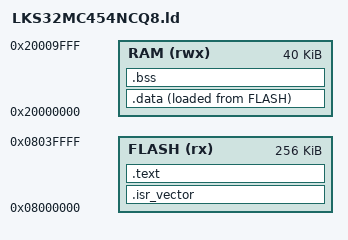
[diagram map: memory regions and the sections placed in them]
/* LKS32MC454NCQ8: 256 KB flash @ 0x08000000, 40 KB SRAM */
ENTRY(Reset_Handler)

MEMORY
{
    FLASH (rx)  : ORIGIN = 0x08000000, LENGTH = 256K
    RAM   (rwx) : ORIGIN = 0x20000000, LENGTH = 40K
}

_estack = ORIGIN(RAM) + LENGTH(RAM);

SECTIONS
{
    .isr_vector :
    {
        . = ALIGN(4);
        KEEP(*(.isr_vector))
        . = ALIGN(4);
    } > FLASH

    .text :
    {
        . = ALIGN(4);
        *(.text*)
        *(.rodata*)
        KEEP(*(.init))
        KEEP(*(.fini))
        . = ALIGN(4);
        _etext = .;
    } > FLASH

    _sidata = LOADADDR(.data);

    .data :
    {
        . = ALIGN(4);
        _sdata = .;
        *(.data*)
        . = ALIGN(4);
        _edata = .;
    } > RAM AT > FLASH

    .bss :
    {
        . = ALIGN(4);
        _sbss = .;
        *(.bss*)
        *(COMMON)
        . = ALIGN(4);
        _ebss = .;
    } > RAM

    /DISCARD/ :
    {
        *(.ARM.exidx*)
        *(.ARM.extab*)
    }
}
